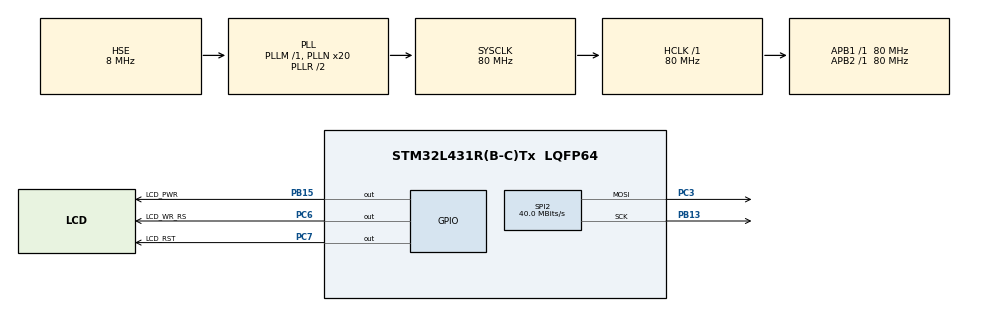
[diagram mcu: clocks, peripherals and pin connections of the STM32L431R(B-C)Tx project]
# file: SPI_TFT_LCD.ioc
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Mcu.Family=STM32L4
Mcu.Name=STM32L431R(B-C)Tx
Mcu.Package=LQFP64
NVIC.PriorityGroup=NVIC_PRIORITYGROUP_4
PB13.Mode=TX_Only_Simplex_Unidirect_Master
PB13.Signal=SPI2_SCK
PB15.GPIO_Label=LCD_PWR
PB15.Signal=GPIO_Output
PC14-OSC32_IN\ (PC14).Mode=LSE-External-Oscillator
PC14-OSC32_IN\ (PC14).Signal=RCC_OSC32_IN
PC15-OSC32_OUT\ (PC15).Mode=LSE-External-Oscillator
PC15-OSC32_OUT\ (PC15).Signal=RCC_OSC32_OUT
PC3.Mode=TX_Only_Simplex_Unidirect_Master
PC3.Signal=SPI2_MOSI
PC6.GPIO_Label=LCD_WR_RS
PC6.Signal=GPIO_Output
PC7.GPIO_Label=LCD_RST
PC7.Signal=GPIO_Output
PH0-OSC_IN\ (PH0).Mode=HSE-External-Oscillator
PH0-OSC_IN\ (PH0).Signal=RCC_OSC_IN
PH1-OSC_OUT\ (PH1).Mode=HSE-External-Oscillator
PH1-OSC_OUT\ (PH1).Signal=RCC_OSC_OUT
ProjectManager.HeapSize=0x200
ProjectManager.StackSize=0x400
ProjectManager.TargetToolchain=SW4STM32
RCC.ADCFreq_Value=32000000
RCC.AHBFreq_Value=80000000
RCC.APB1Freq_Value=80000000
RCC.APB1TimFreq_Value=80000000
RCC.APB2Freq_Value=80000000
RCC.APB2TimFreq_Value=80000000
RCC.CortexFreq_Value=80000000
RCC.HCLKFreq_Value=80000000
RCC.HSE_VALUE=8000000
RCC.HSI48_VALUE=48000000
RCC.HSI_VALUE=16000000
RCC.MSI_VALUE=4000000
RCC.PLLN=20
RCC.PLLSourceVirtual=RCC_PLLSOURCE_HSE
RCC.SYSCLKFreq_VALUE=80000000
RCC.SYSCLKSource=RCC_SYSCLKSOURCE_PLLCLK
RCC.VCOOutputFreq_Value=160000000
SPI2.BaudRatePrescaler=SPI_BAUDRATEPRESCALER_2
SPI2.CLKPhase=SPI_PHASE_2EDGE
SPI2.CLKPolarity=SPI_POLARITY_HIGH
SPI2.CalculateBaudRate=40.0 MBits/s
SPI2.DataSize=SPI_DATASIZE_8BIT
SPI2.Direction=SPI_DIRECTION_2LINES
SPI2.Mode=SPI_MODE_MASTER
SPI2.VirtualType=VM_MASTER
board=custom

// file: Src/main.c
/* USER CODE BEGIN Header */
/**
  ******************************************************************************
  * @file           : main.c
  * @brief          : Main program body
  ******************************************************************************
  * @attention
  *
  * <h2><center>&copy; Copyright (c) 2019 STMicroelectronics.
  * All rights reserved.</center></h2>
  *
  * This software component is licensed by ST under BSD 3-Clause license,
  * the "License"; You may not use this file except in compliance with the
  * License. You may obtain a copy of the License at:
  *                        opensource.org/licenses/BSD-3-Clause
  *
  ******************************************************************************
  */
/* USER CODE END Header */

#include <bear.h>
#include "main.h"
#include "spi.h"
#include "gpio.h"

/* USER CODE BEGIN Includes */
#include "lcd_spi2_drv.h"
/* USER CODE END Includes */

void SystemClock_Config(void);

int main(void)
{

  /* MCU Configuration--------------------------------------------------------*/

  /* Reset of all peripherals, Initializes the Flash interface and the Systick. */
  HAL_Init();

  /* Configure the system clock */
  SystemClock_Config();

  /* Initialize all configured peripherals */
  MX_GPIO_Init();
  MX_SPI2_Init();
  /* USER CODE BEGIN 2 */

  LCD_Init();

    //以下9行代码是测试画线、画矩形、画圆使用，如非必要，请勿取消注释
//      LCD_Draw_ColorLine(0,120,240,120,RED);		//画水平线
//      LCD_Draw_ColorLine(0,0,240,240,BLUE);	  	//画斜线(从左到右，45°)
//      LCD_Draw_ColorLine(0,240,240,0,GREEN);		//画斜线(从右到左，45°)
//      LCD_Draw_ColorLine(120,0,120,240,YELLOW);	//画垂直线
//      LCD_Draw_ColorLine(180,0,60,240,RED);			//画斜线(从左到右，120°)
//      LCD_Draw_ColorLine(60,0,180,240,RED);			//画斜线(从右到左，60°)
//      LCD_Draw_ColorLine(0,60,240,180,RED);			//画斜线(从左到右，180°)
//      LCD_Draw_ColorLine(0,180,240,60,RED);			//画斜线(从左到右，30°)
//      LCD_Draw_ColorRect(60,60,180,180,PINK);		//画矩形
//      LCD_Draw_ColorCircle(120,120,85, GBLUE);	//画圆
//    LCD_ShowChar(0,0,'A',BLACK,BLUE,12);
//    LCD_ShowChar(6,12,'B',BLACK,YELLOW,16);
//    LCD_ShowChar(12,28,'C',BLACK,GREEN,24);
//    LCD_ShowChar(18,52,'D',BLACK,PINK,32);
//    LCD_ShowCharStr(60,240-32-24-24-24,120,"Powerd BY",BLACK,GREEN,24);
//    LCD_ShowCharStr(36,240-32-24-24,150,"HUAWEI LiteOS",BLACK,YELLOW,24);
//    LCD_ShowCharStr(28,240-32-24,176,"Mculover666",BLACK,BLUE,32);
//    LCD_ShowCharStr(12,240-24,240,"Copyright (c) 2019",BLACK,PINK,24);
//    LCD_Draw_ColorSixPointStar(150,65,40,RED);

    LCD_Show_Image(0,0,240,240,gImage_bear);
    LCD_ShowCharStr(80,240-24,140,"Alex Wu",WHITE,BLUE,24);
  /* USER CODE END 2 */

  /* Infinite loop */
  while (1)
  {

  }
}

void SystemClock_Config(void)
{
  RCC_OscInitTypeDef RCC_OscInitStruct = {0};
  RCC_ClkInitTypeDef RCC_ClkInitStruct = {0};

  /** Initializes the CPU, AHB and APB busses clocks
  */
  RCC_OscInitStruct.OscillatorType = RCC_OSCILLATORTYPE_HSE;
  RCC_OscInitStruct.HSEState = RCC_HSE_ON;
  RCC_OscInitStruct.PLL.PLLState = RCC_PLL_ON;
  RCC_OscInitStruct.PLL.PLLSource = RCC_PLLSOURCE_HSE;
  RCC_OscInitStruct.PLL.PLLM = 1;
  RCC_OscInitStruct.PLL.PLLN = 20;
  RCC_OscInitStruct.PLL.PLLP = RCC_PLLP_DIV7;
  RCC_OscInitStruct.PLL.PLLQ = RCC_PLLQ_DIV2;
  RCC_OscInitStruct.PLL.PLLR = RCC_PLLR_DIV2;
  if (HAL_RCC_OscConfig(&RCC_OscInitStruct) != HAL_OK)
  {
    Error_Handler();
  }
  /** Initializes the CPU, AHB and APB busses clocks
  */
  RCC_ClkInitStruct.ClockType = RCC_CLOCKTYPE_HCLK|RCC_CLOCKTYPE_SYSCLK
                              |RCC_CLOCKTYPE_PCLK1|RCC_CLOCKTYPE_PCLK2;
  RCC_ClkInitStruct.SYSCLKSource = RCC_SYSCLKSOURCE_PLLCLK;
  RCC_ClkInitStruct.AHBCLKDivider = RCC_SYSCLK_DIV1;
  RCC_ClkInitStruct.APB1CLKDivider = RCC_HCLK_DIV1;
  RCC_ClkInitStruct.APB2CLKDivider = RCC_HCLK_DIV1;

  if (HAL_RCC_ClockConfig(&RCC_ClkInitStruct, FLASH_LATENCY_4) != HAL_OK)
  {
    Error_Handler();
  }
  /** Configure the main internal regulator output voltage
  */
  if (HAL_PWREx_ControlVoltageScaling(PWR_REGULATOR_VOLTAGE_SCALE1) != HAL_OK)
  {
    Error_Handler();
  }
}

void Error_Handler(void)
{
}

/************************ (C) COPYRIGHT STMicroelectronics *****END OF FILE****/
